# R7KA8T2AD register map
Vendor: Renesas Electronics Corporation; Series: RA8; File version: 1.10.02
CPU: CM85 r0p2, little endian, MPU, FPU, VTOR, 4 interrupt priority bits, 96 interrupts
Registers are 32-bit, read-write, reset 0x0 unless marked. A register's access mark holds for its fields unless they carry their own. Offsets are from the block's base; [hi:lo] are bit positions; {n}, {i} and the like mark numbered series; 'fields as' and 'values as' point back to an identical list.

## POEG_NS — Port Output Enable Module for GPT
Base 0x50212000
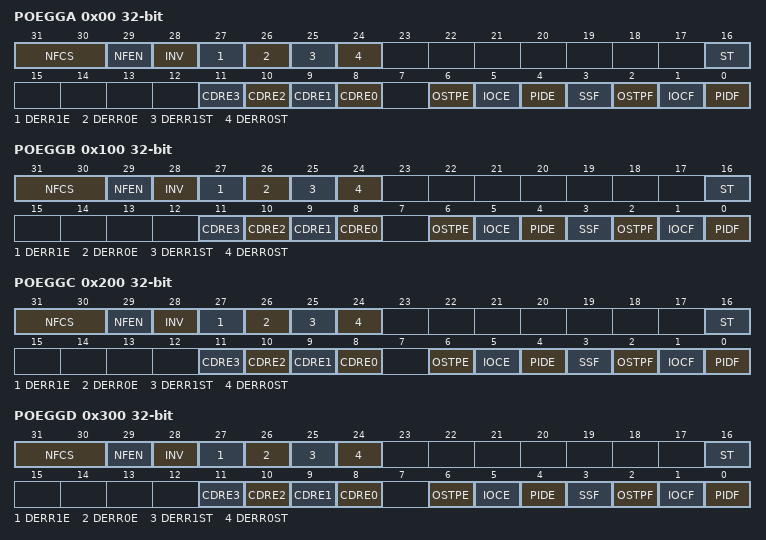
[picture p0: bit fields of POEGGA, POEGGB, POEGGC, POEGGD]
0x00 POEGGA — POEG Group A Setting Register
  [31:30] NFCS — Noise Filter Clock Select
    0=Sample GTETRGn pin input level three times every PCLKB; 1=Sample GTETRGn pin input level three times every PCLKB/8; 2=Sample GTETRGn pin input level three times every PCLKB/32; 3=Sample GTETRGn pin input level three times every PCLKB/128
  [29] NFEN — Noise Filter Enable
    0=Disable noise filtering; 1=Enable noise filtering
  [28] INV — GTETRGn Input Reverse
    0=Input GTETRGn as-is; 1=Input GTETRGn in reverse
  [27] DERR1E
    0=Disable output-disable request when overcurrent detection window notification from DSMIF1 is detected; 1=Enable output-disable request when overcurrent detection window notification from DSMIF1 is detected
  [26] DERR0E
    0=Disable output-disable request when overcurrent detection window notification from DSMIF0 is detected; 1=Enable output-disable request when overcurrent detection window notification from DSMIF0 is detected
  [25] DERR1ST
    0=No overcurrent detection window notification from DSMIF1 is detected; 1=Overcurrent detection window notification from DSMIF1 is detected
  [24] DERR0ST
    0=No overcurrent detection window notification from DSMIF0 is detected; 1=Overcurrent detection window notification from DSMIF0 is detected
  [16] ST ro — GTETRGn Input Status Flag
    0=GTETRGn input after filtering was 0; 1=GTETRGn input after filtering was 1
  [n+8] CDRE{n} (n=0..3)
    0=Disable output-disable request from ACMPHS{n}; 1=Enable output-disable request from ACMPHS{n}
  [6] OSTPE — Oscillation Stop Detection Enable
    0=Disable output-disable requests from oscillation stop detection; 1=Enable output-disable requests from oscillation stop detection
  [5] IOCE — Enable for GPT Output-Disable Request
    0=Disable output-disable requests from GPT; 1=Enable output-disable requests from GPT
  [4] PIDE — Port Input Detection Enable
    0=Disable output-disable requests from the GTETRGn pins; 1=Enable output-disable requests from the GTETRGn pins
  [3] SSF — Software Stop Flag
    0=No output-disable request from software occurred; 1=Output-disable request from software occurred
  [2] OSTPF — Oscillation Stop Detection Flag
    0=No output-disable request from oscillation stop detection occurred; 1=Output-disable request from oscillation stop detection occurred
  [1] IOCF — Detection Flag for GPT or ACMPHS Output-Disable Request
    0=No output-disable request from GPT or comparator interrupt occurred; 1=Output-disable request from GPT or comparator interrupt occurred
  [0] PIDF — Port Input Detection Flag
    0=No output-disable request from the GTETRGn pin occurred; 1=Output-disable request from the GTETRGn pin occurred
0x100 POEGGB — POEG Group B Setting Register
  fields as POEGGA
0x200 POEGGC — POEG Group C Setting Register
  fields as POEGGA
0x300 POEGGD — POEG Group D Setting Register
  fields as POEGGA

## CRC_NS — Cyclic Redundancy Check Calculator
Base 0x50310000
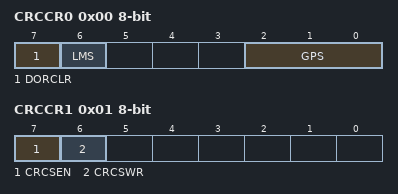
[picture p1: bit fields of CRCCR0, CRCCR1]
0x00 CRCCR0 8-bit — CRC Control Register 0
  [7] DORCLR wo — CRCDOR/CRCDOR_HA/CRCDOR_BY Register Clear
    0=No effect; 1=Clear the CRCDOR/CRCDOR_HA/CRCDOR_BY register
  [6] LMS — CRC Calculation Switching
    0=Generate CRC code for LSB-first communication; 1=Generate CRC code for MSB-first communication
  [2:0] GPS — CRC Generating Polynomial Switching
    1=8-bit CRC-8 (X8 + X2 + X + 1); 2=16-bit CRC-16 (X16 + X15 + X2 + 1); 3=16-bit CRC-CCITT (X16 + X12 + X5 + 1); 4=32-bit CRC-32 (X32 + X26 + X23 + X22 + X16 + X12 + X11 +X10 + X8 + X7 + X5 + X4 + X2 + X + 1); 5=32-bit CRC-32C (X32 + X28 + X27 + X26 + X25 + X23 + X22 + X20 + X19 + X18 + X14 + X13 + X11 + X10 + X9 + X8 + X6 + 1); other=Others (No calculation is executed)
0x01 CRCCR1 8-bit — CRC Control Register 1
  [7] CRCSEN — Snoop Enable
    0=Disabled; 1=Enabled
  [6] CRCSWR — Snoop-On-Write/Read Switch
    0=Snoop-on-read; 1=Snoop-on-write
0x04 CRCDIR — CRC Data Input Register
0x04 CRCDIR_BY 8-bit (alternate view of CRCDIR) — CRC Data Input Register
0x08 CRCDOR — CRC Data Output Register
0x08 CRCDOR_HA 16-bit (alternate view of CRCDOR) — CRC Data Output Register
0x08 CRCDOR_BY 8-bit (alternate view of CRCDOR) — CRC Data Output Register
0x0C CRCSAR 16-bit — Snoop Address Register
  [13:0] CRCSA — Register Snoop Address

## DSMIF0_NS — Delta-Sigma Modulators
Base 0x5032A000
Same registers: DSMIF1_NS 0x5032A800
0x00 DSCCSCR — Core Clock Selection Control Register
  [1:0] CLKSEL — Selection of core clock (CCLK)
    0=PCLKA; 1=DSMIFCLK; 2=GPTCLK; 3=Setting prohibited
